# AST1080 register map
File version: 1.0
CPU: CM4 r0p1, little endian, MPU, FPU, 4 interrupt priority bits, 256 interrupts
Registers are 32-bit, read-write, reset 0x0 unless marked. A register's access mark holds for its fields unless they carry their own. Offsets are from the block's base; [hi:lo] are bit positions; {n}, {i} and the like mark numbered series; 'fields as' and 'values as' point back to an identical list.

## spipf
Base 0x74C15000
Same registers: spipf1 0x74C16000, spipf2 0x74C17000
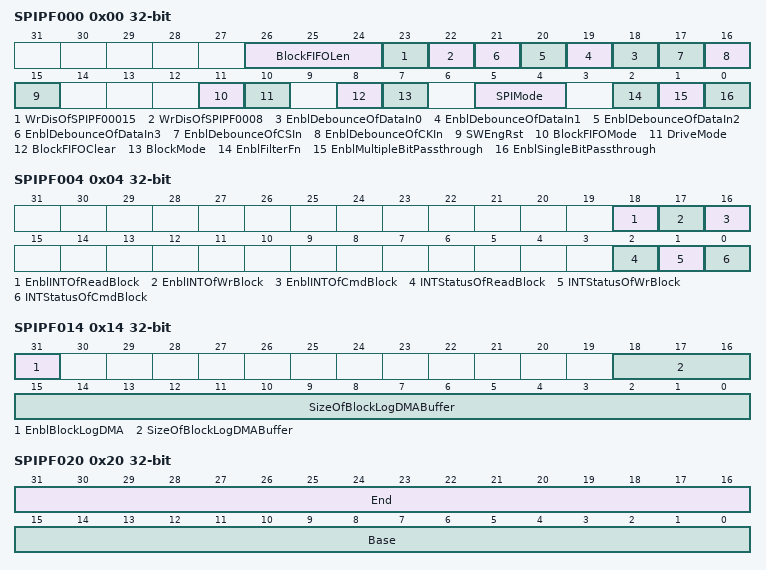
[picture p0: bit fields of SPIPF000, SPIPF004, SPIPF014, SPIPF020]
0x00 SPIPF000 — Engine Control Register
  [26:24] BlockFIFOLen ro — Block FIFO length
  [23] WrDisOfSPIPF00015 — Write Disable of SPIPF000[15]
  [22] WrDisOfSPIPF0008 — Write Disable of SPIPF000[8]
  [n+18] EnblDebounceOfDataIn{n} (n=0..3) — Enable Debounce of DataIn[{n}]
  [17] EnblDebounceOfCSIn — Enable Debounce of CSIn
  [16] EnblDebounceOfCKIn — Enable Debounce of CKIn
  [15] SWEngRst — SW Engine Reset
    1=Reset; 0=NOP
  [11] BlockFIFOMode
    1=Store_The_Latest_The_Lastest_Orverrides; 0=Store_The_Oldest_Stops_When_FIFO_Full
  [10] DriveMode
    1=Drive_DataOut_After_CS_Is_Low; 0=Drive_DataOut0_SPI_Or_DataOut30_QPI_Before_CS_Is_Low
  [8] BlockFIFOClear
    1=Clear_Block_FIFO
  [7] BlockMode
    1=Block_A_Command_By_One_Extra_CLK; 0=Block_A_Command_By_Deasserting_CS_Early
  [5:4] SPIMode
  [2] EnblFilterFn — Enable Filter function
  [1] EnblMultipleBitPassthrough — Enable Multiple Bit Passthrough
  [0] EnblSingleBitPassthrough — Enable Single Bit Passthrough
0x04 SPIPF004 — Interrupt Enable and Status Register
  [18] EnblINTOfReadBlock — Enable Interrupt of Read Block
  [17] EnblINTOfWrBlock — Enable Interrupt of Write Block
  [16] EnblINTOfCmdBlock — Enable Interrupt of Command Block
  [2] INTStatusOfReadBlock — Interrupt Status of Read Block
  [1] INTStatusOfWrBlock — Interrupt Status of Write Block
  [0] INTStatusOfCmdBlock — Interrupt Status of Command Block
0x08 SPIPF008 — EAR and Over Speed Register
  [7:0] CurExtendAddrRegRxdFromSPIMaster ro — Current Extend Address Register Received from SPI master
0x0C SPIPF00C — Block FIFO Data Register
  [31:0] ReadDataOfBlockFIFO ro
0x10 SPIPF010 — Block Log DMA Base Address
  [31:2] BlockLogDMABaseAddr
0x14 SPIPF014 — Block Log DMA Size
  [31] EnblBlockLogDMA — Enable Block Log DMA
  [18:0] SizeOfBlockLogDMABuffer
0x18 SPIPF018 — Block Log DMA Write Pointer
  [17:0] BlockLogDMAWrPointer ro
0x20 SPIPF020 — CS0 range
  [31:16] End, [15:0] Base
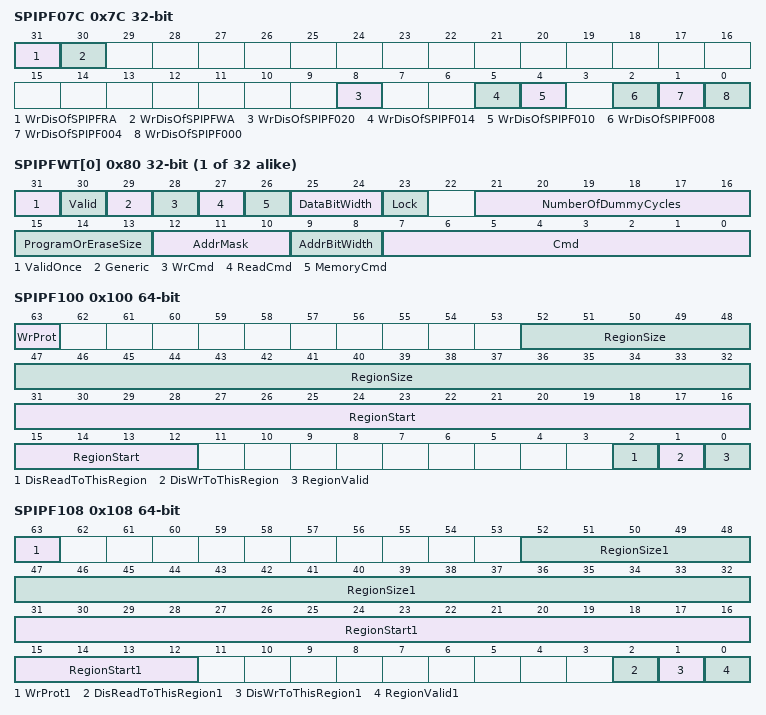
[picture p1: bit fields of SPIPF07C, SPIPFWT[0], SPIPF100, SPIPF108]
0x7C SPIPF07C — Write Disable Register
  [31] WrDisOfSPIPFRA — Write Disable of SPIPFRA
  [30] WrDisOfSPIPFWA — Write Disable of SPIPFWA
  [8] WrDisOfSPIPF020 — Write Disable of SPIPF020
  [5] WrDisOfSPIPF014 — Write Disable of SPIPF014
  [4] WrDisOfSPIPF010 — Write Disable of SPIPF010
  [2] WrDisOfSPIPF008 — Write Disable of SPIPF008
  [1] WrDisOfSPIPF004 — Write Disable of SPIPF004
  [0] WrDisOfSPIPF000 — Write Disable of SPIPF000
{0x80+4i} SPIPFWT[{i}] (i=0..31) — Allow Command Table \#1 $\sim$ \#32
  [31] ValidOnce
    0=0_Comes
  [30] Valid
  [29] Generic
  [28] WrCmd — Write Command
  [27] ReadCmd — Read Command
  [26] MemoryCmd — Memory Command
  [25:24] DataBitWidth
  [23] Lock
  [21:16] NumberOfDummyCycles
  [15:13] ProgramOrEraseSize
  [12:10] AddrMask — Address Mask
  [9:8] AddrBitWidth — Address Bit width
  [7:0] Cmd — Command
0x100 SPIPF100 64-bit — Region 00 setting
  [63] WrProt — Write Protection
  [52:32] RegionSize
  [31:12] RegionStart
  [2] DisReadToThisRegion — Disable Read to this region
  [1] DisWrToThisRegion — Disable Write to this region
  [0] RegionValid
0x108 SPIPF108 64-bit — Region 01 setting
  [63] WrProt1 — Write Protection
  [52:32] RegionSize1 — Region Size
  [31:12] RegionStart1 — Region Start
  [2] DisReadToThisRegion1 — Disable Read to this region
  [1] DisWrToThisRegion1 — Disable Write to this region
  [0] RegionValid1 — Region Valid
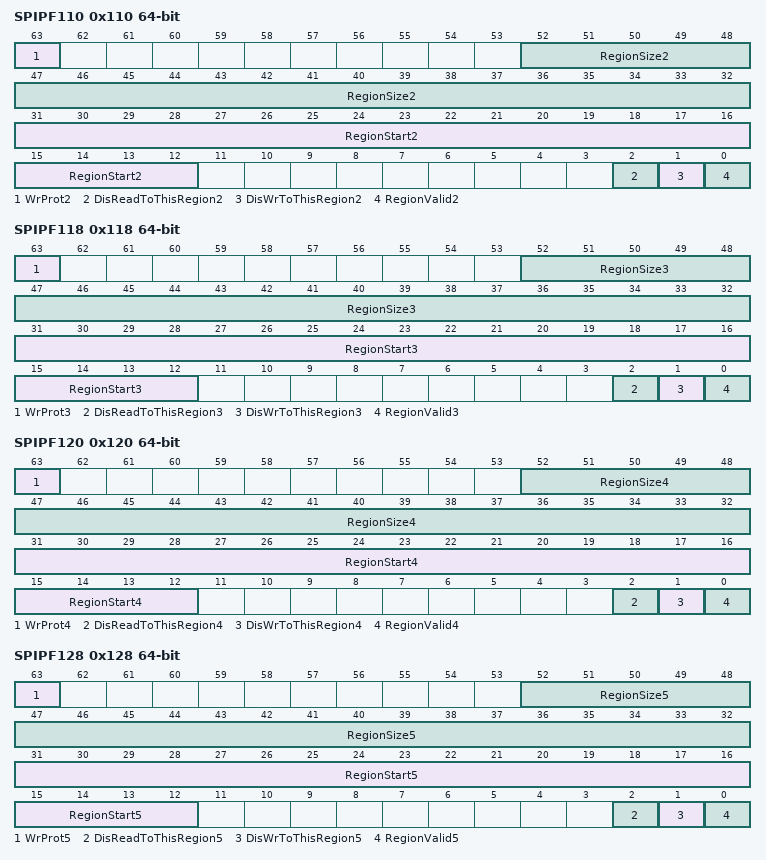
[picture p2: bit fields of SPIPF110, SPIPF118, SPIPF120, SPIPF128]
0x110 SPIPF110 64-bit — Region 02 setting
  [63] WrProt2 — Write Protection
  [52:32] RegionSize2 — Region Size
  [31:12] RegionStart2 — Region Start
  [2] DisReadToThisRegion2 — Disable Read to this region
  [1] DisWrToThisRegion2 — Disable Write to this region
  [0] RegionValid2 — Region Valid
0x118 SPIPF118 64-bit — Region 03 setting
  [63] WrProt3 — Write Protection
  [52:32] RegionSize3 — Region Size
  [31:12] RegionStart3 — Region Start
  [2] DisReadToThisRegion3 — Disable Read to this region
  [1] DisWrToThisRegion3 — Disable Write to this region
  [0] RegionValid3 — Region Valid
0x120 SPIPF120 64-bit — Region 04 setting
  [63] WrProt4 — Write Protection
  [52:32] RegionSize4 — Region Size
  [31:12] RegionStart4 — Region Start
  [2] DisReadToThisRegion4 — Disable Read to this region
  [1] DisWrToThisRegion4 — Disable Write to this region
  [0] RegionValid4 — Region Valid
0x128 SPIPF128 64-bit — Region 05 setting
  [63] WrProt5 — Write Protection
  [52:32] RegionSize5 — Region Size
  [31:12] RegionStart5 — Region Start
  [2] DisReadToThisRegion5 — Disable Read to this region
  [1] DisWrToThisRegion5 — Disable Write to this region
  [0] RegionValid5 — Region Valid
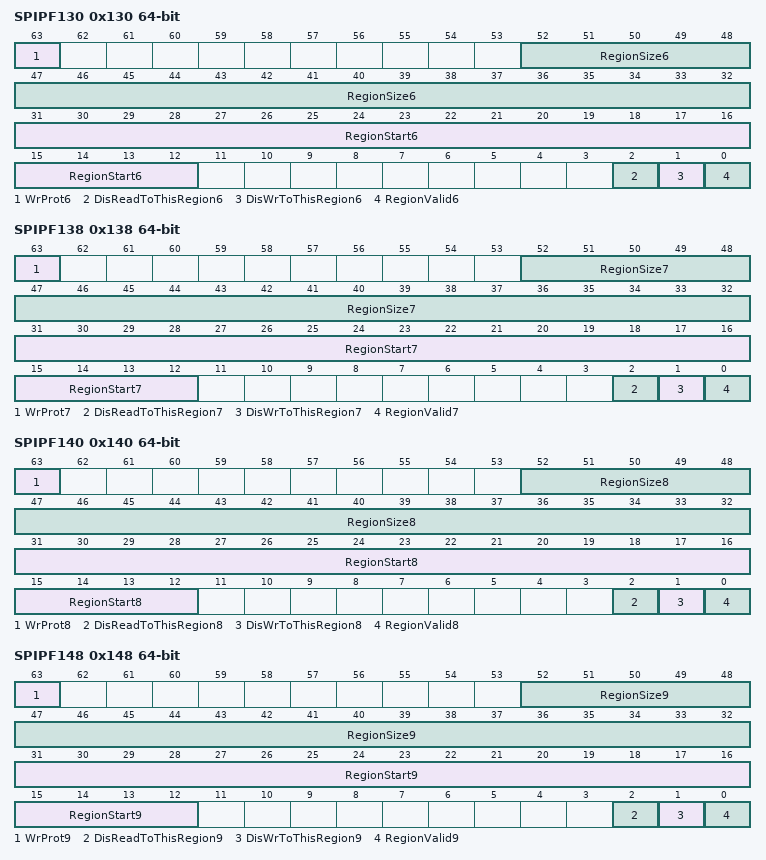
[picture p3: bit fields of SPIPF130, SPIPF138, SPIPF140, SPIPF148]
0x130 SPIPF130 64-bit — Region 06 setting
  [63] WrProt6 — Write Protection
  [52:32] RegionSize6 — Region Size
  [31:12] RegionStart6 — Region Start
  [2] DisReadToThisRegion6 — Disable Read to this region
  [1] DisWrToThisRegion6 — Disable Write to this region
  [0] RegionValid6 — Region Valid
0x138 SPIPF138 64-bit — Region 07 setting
  [63] WrProt7 — Write Protection
  [52:32] RegionSize7 — Region Size
  [31:12] RegionStart7 — Region Start
  [2] DisReadToThisRegion7 — Disable Read to this region
  [1] DisWrToThisRegion7 — Disable Write to this region
  [0] RegionValid7 — Region Valid
0x140 SPIPF140 64-bit — Region 08 setting
  [63] WrProt8 — Write Protection
  [52:32] RegionSize8 — Region Size
  [31:12] RegionStart8 — Region Start
  [2] DisReadToThisRegion8 — Disable Read to this region
  [1] DisWrToThisRegion8 — Disable Write to this region
  [0] RegionValid8 — Region Valid
0x148 SPIPF148 64-bit — Region 09 setting
  [63] WrProt9 — Write Protection
  [52:32] RegionSize9 — Region Size
  [31:12] RegionStart9 — Region Start
  [2] DisReadToThisRegion9 — Disable Read to this region
  [1] DisWrToThisRegion9 — Disable Write to this region
  [0] RegionValid9 — Region Valid
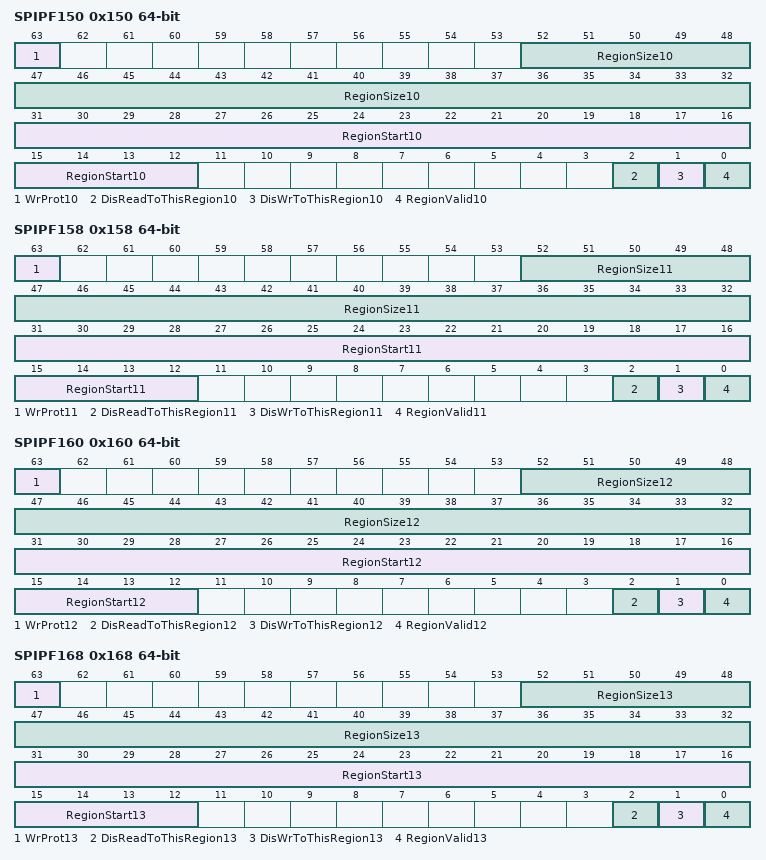
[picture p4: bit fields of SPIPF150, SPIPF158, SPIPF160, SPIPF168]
0x150 SPIPF150 64-bit — Region 10 setting
  [63] WrProt10 — Write Protection
  [52:32] RegionSize10 — Region Size
  [31:12] RegionStart10 — Region Start
  [2] DisReadToThisRegion10 — Disable Read to this region
  [1] DisWrToThisRegion10 — Disable Write to this region
  [0] RegionValid10 — Region Valid
0x158 SPIPF158 64-bit — Region 11 setting
  [63] WrProt11 — Write Protection
  [52:32] RegionSize11 — Region Size
  [31:12] RegionStart11 — Region Start
  [2] DisReadToThisRegion11 — Disable Read to this region
  [1] DisWrToThisRegion11 — Disable Write to this region
  [0] RegionValid11 — Region Valid
0x160 SPIPF160 64-bit — Region 12 setting
  [63] WrProt12 — Write Protection
  [52:32] RegionSize12 — Region Size
  [31:12] RegionStart12 — Region Start
  [2] DisReadToThisRegion12 — Disable Read to this region
  [1] DisWrToThisRegion12 — Disable Write to this region
  [0] RegionValid12 — Region Valid
0x168 SPIPF168 64-bit — Region 13 setting
  [63] WrProt13 — Write Protection
  [52:32] RegionSize13 — Region Size
  [31:12] RegionStart13 — Region Start
  [2] DisReadToThisRegion13 — Disable Read to this region
  [1] DisWrToThisRegion13 — Disable Write to this region
  [0] RegionValid13 — Region Valid
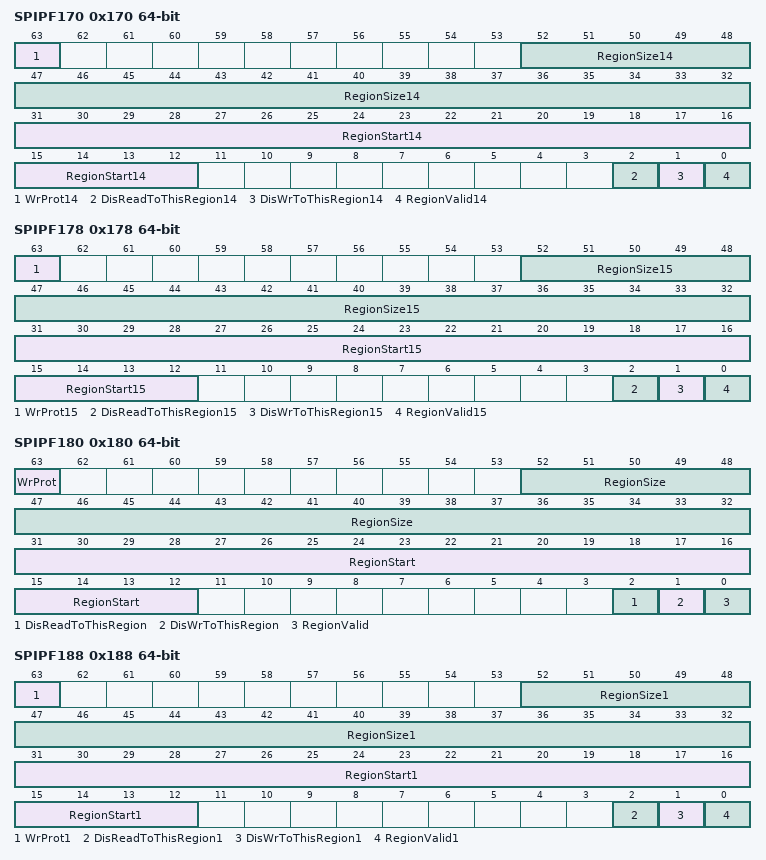
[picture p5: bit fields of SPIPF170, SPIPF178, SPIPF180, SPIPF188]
0x170 SPIPF170 64-bit — Region 14 setting
  [63] WrProt14 — Write Protection
  [52:32] RegionSize14 — Region Size
  [31:12] RegionStart14 — Region Start
  [2] DisReadToThisRegion14 — Disable Read to this region
  [1] DisWrToThisRegion14 — Disable Write to this region
  [0] RegionValid14 — Region Valid
0x178 SPIPF178 64-bit — Region 15 setting
  [63] WrProt15 — Write Protection
  [52:32] RegionSize15 — Region Size
  [31:12] RegionStart15 — Region Start
  [2] DisReadToThisRegion15 — Disable Read to this region
  [1] DisWrToThisRegion15 — Disable Write to this region
  [0] RegionValid15 — Region Valid
0x180 SPIPF180 64-bit — Region 16 setting
  fields as SPIPF100
0x188 SPIPF188 64-bit — Region 17 setting
  fields as SPIPF108
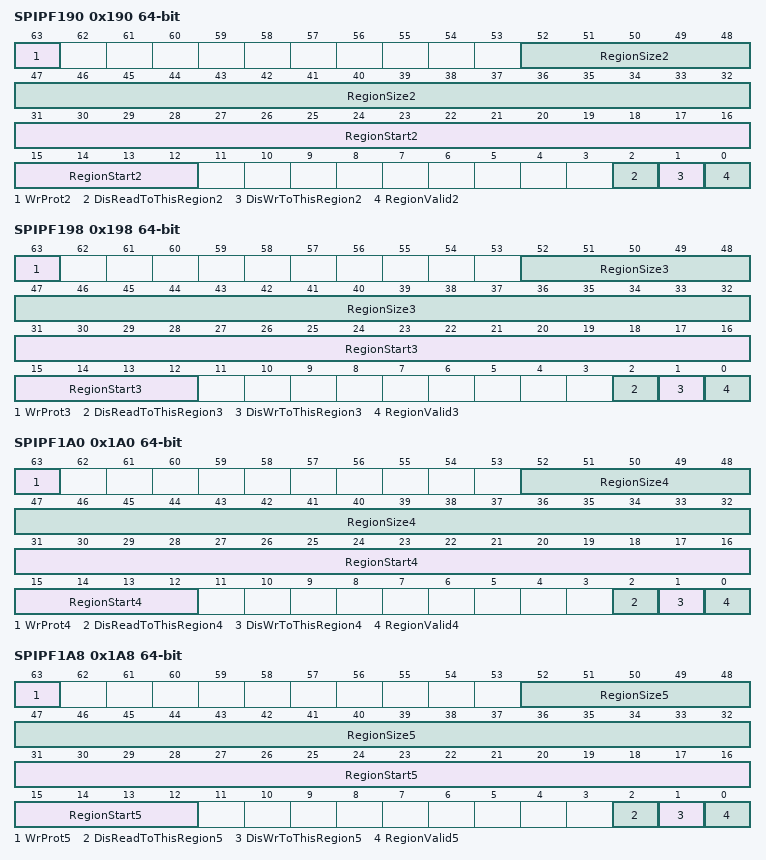
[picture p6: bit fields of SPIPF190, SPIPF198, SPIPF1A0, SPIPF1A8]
0x190 SPIPF190 64-bit — Region 18 setting
  fields as SPIPF110
0x198 SPIPF198 64-bit — Region 19 setting
  fields as SPIPF118
0x1A0 SPIPF1A0 64-bit — Region 20 setting
  fields as SPIPF120
0x1A8 SPIPF1A8 64-bit — Region 21 setting
  fields as SPIPF128
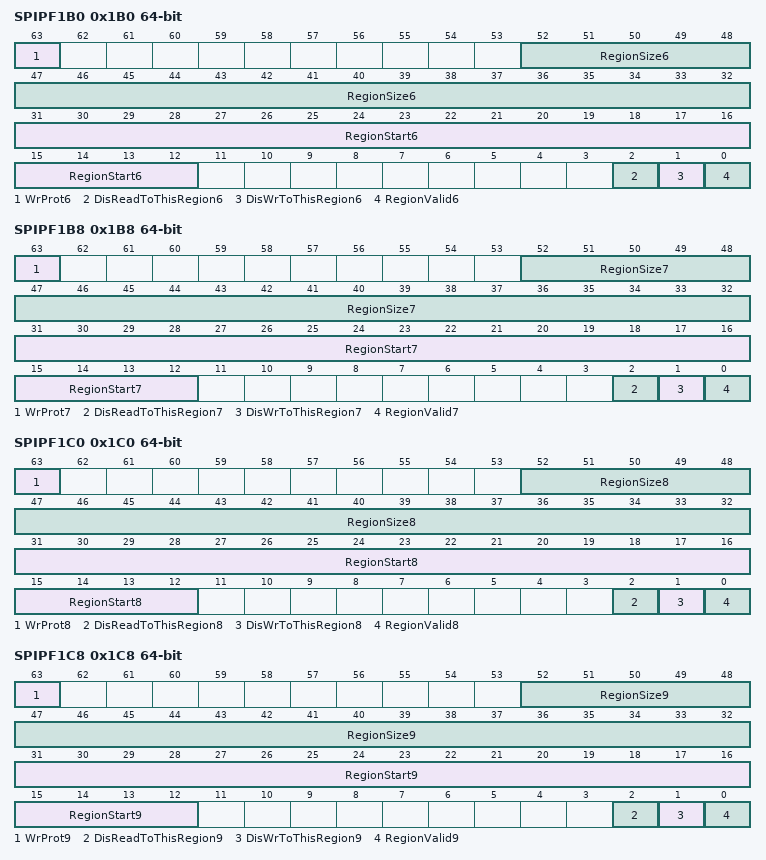
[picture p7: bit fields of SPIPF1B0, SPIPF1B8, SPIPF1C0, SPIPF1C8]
0x1B0 SPIPF1B0 64-bit — Region 22 setting
  fields as SPIPF130
0x1B8 SPIPF1B8 64-bit — Region 23 setting
  fields as SPIPF138
0x1C0 SPIPF1C0 64-bit — Region 24 setting
  fields as SPIPF140
0x1C8 SPIPF1C8 64-bit — Region 25 setting
  fields as SPIPF148
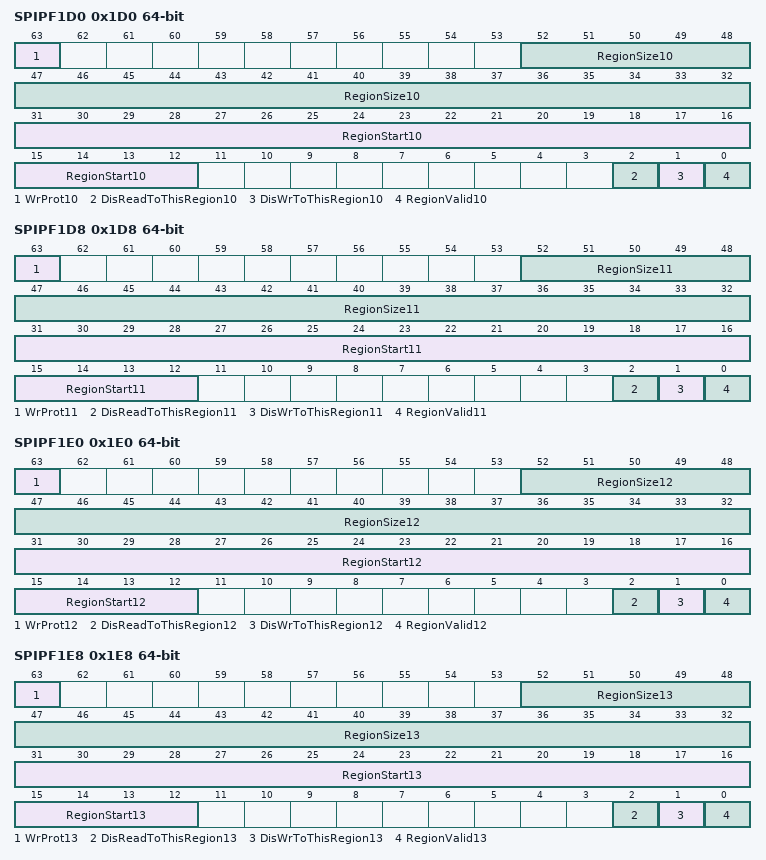
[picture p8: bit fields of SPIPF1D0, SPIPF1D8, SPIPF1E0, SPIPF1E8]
0x1D0 SPIPF1D0 64-bit — Region 26 setting
  fields as SPIPF150
0x1D8 SPIPF1D8 64-bit — Region 27 setting
  fields as SPIPF158
0x1E0 SPIPF1E0 64-bit — Region 28 setting
  fields as SPIPF160
0x1E8 SPIPF1E8 64-bit — Region 29 setting
  fields as SPIPF168
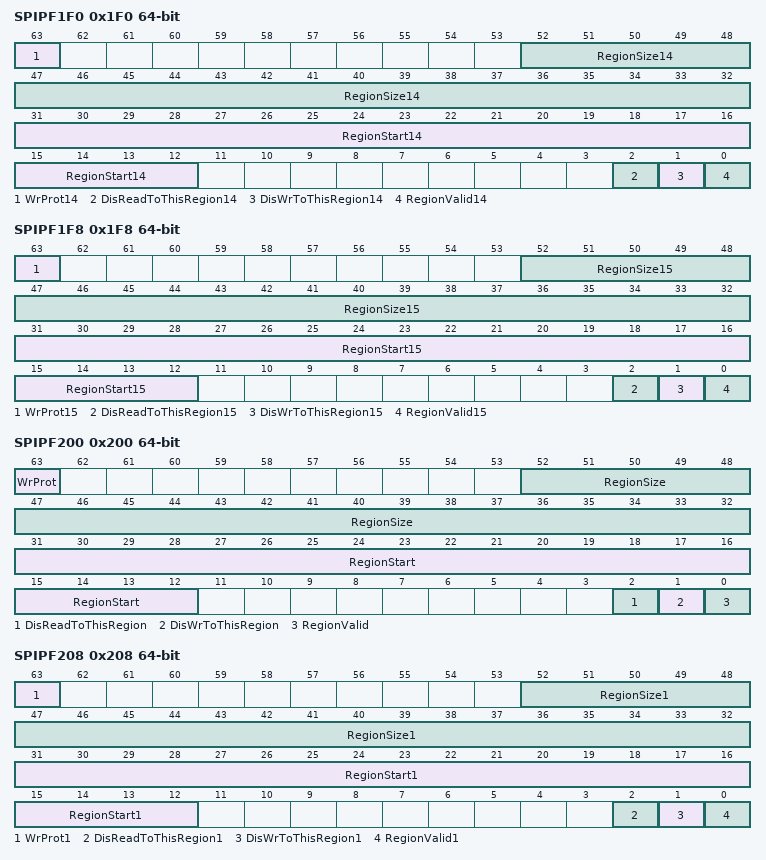
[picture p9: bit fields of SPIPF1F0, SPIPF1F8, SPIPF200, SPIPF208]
0x1F0 SPIPF1F0 64-bit — Region 30 setting
  fields as SPIPF170
0x1F8 SPIPF1F8 64-bit — Region 31 setting
  fields as SPIPF178
0x200 SPIPF200 64-bit — Region 32 setting
  fields as SPIPF100
0x208 SPIPF208 64-bit — Region 33 setting
  fields as SPIPF108
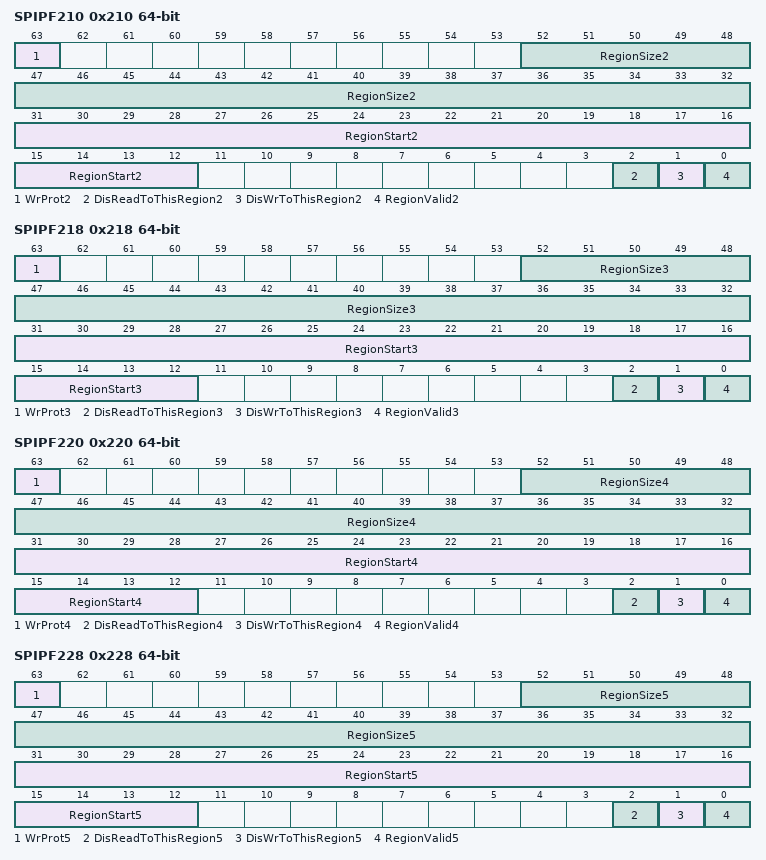
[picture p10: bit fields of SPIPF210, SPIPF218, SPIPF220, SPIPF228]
0x210 SPIPF210 64-bit — Region 34 setting
  fields as SPIPF110
0x218 SPIPF218 64-bit — Region 35 setting
  fields as SPIPF118
0x220 SPIPF220 64-bit — Region 36 setting
  fields as SPIPF120
0x228 SPIPF228 64-bit — Region 37 setting
  fields as SPIPF128
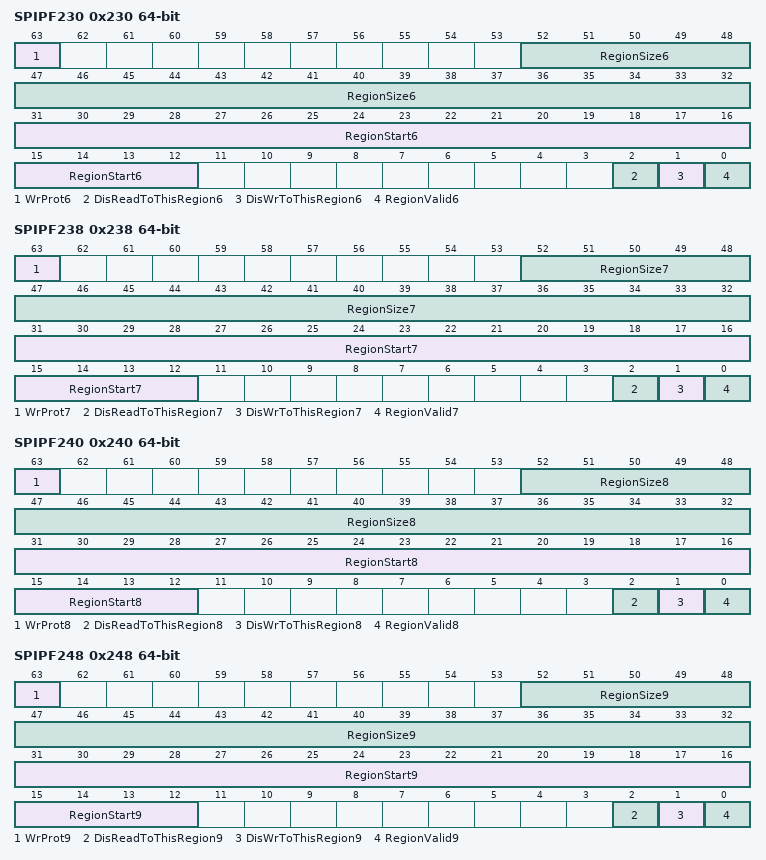
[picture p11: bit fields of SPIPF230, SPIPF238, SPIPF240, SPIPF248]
0x230 SPIPF230 64-bit — Region 38 setting
  fields as SPIPF130
0x238 SPIPF238 64-bit — Region 39 setting
  fields as SPIPF138
0x240 SPIPF240 64-bit — Region 40 setting
  fields as SPIPF140
0x248 SPIPF248 64-bit — Region 41 setting
  fields as SPIPF148
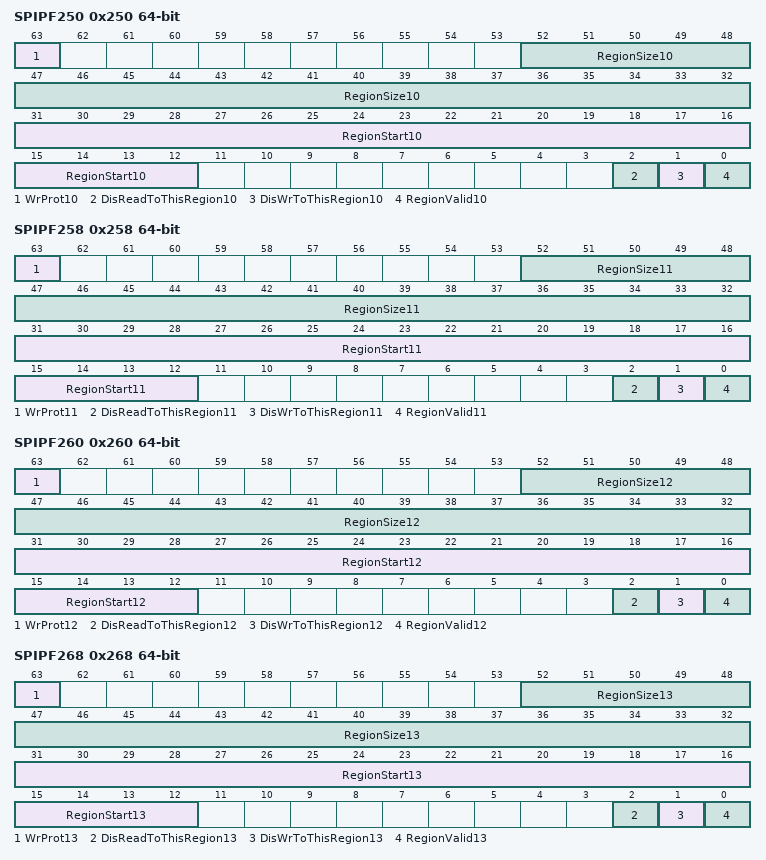
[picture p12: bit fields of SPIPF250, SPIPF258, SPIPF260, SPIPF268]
0x250 SPIPF250 64-bit — Region 42 setting
  fields as SPIPF150
0x258 SPIPF258 64-bit — Region 43 setting
  fields as SPIPF158
0x260 SPIPF260 64-bit — Region 44 setting
  fields as SPIPF160
0x268 SPIPF268 64-bit — Region 45 setting
  fields as SPIPF168
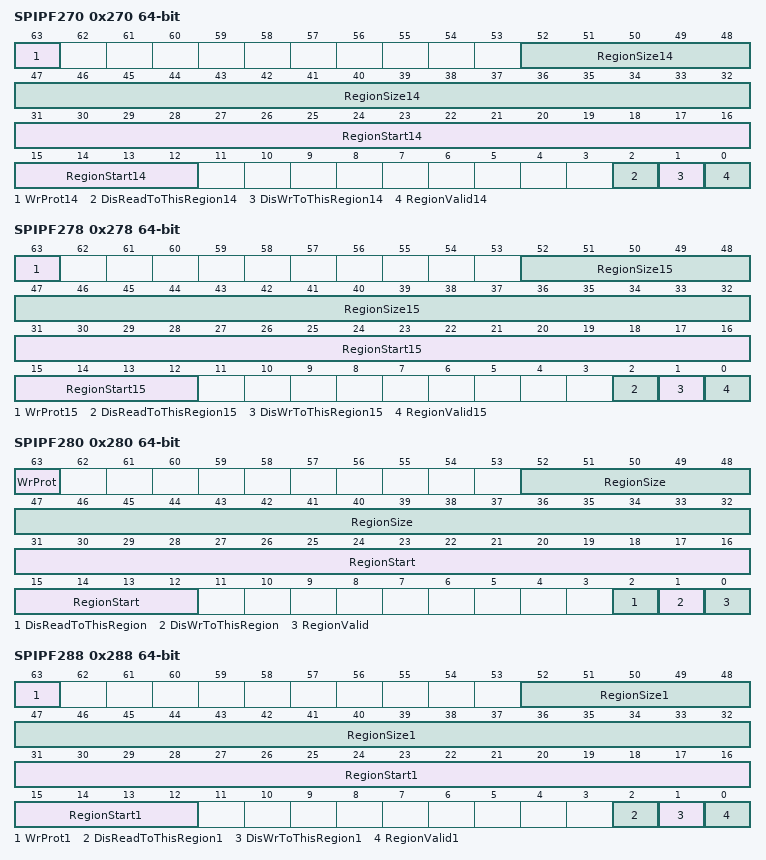
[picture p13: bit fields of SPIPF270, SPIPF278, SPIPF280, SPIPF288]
0x270 SPIPF270 64-bit — Region 46 setting
  fields as SPIPF170
0x278 SPIPF278 64-bit — Region 47 setting
  fields as SPIPF178
0x280 SPIPF280 64-bit — Region 48 setting
  fields as SPIPF100
0x288 SPIPF288 64-bit — Region 49 setting
  fields as SPIPF108
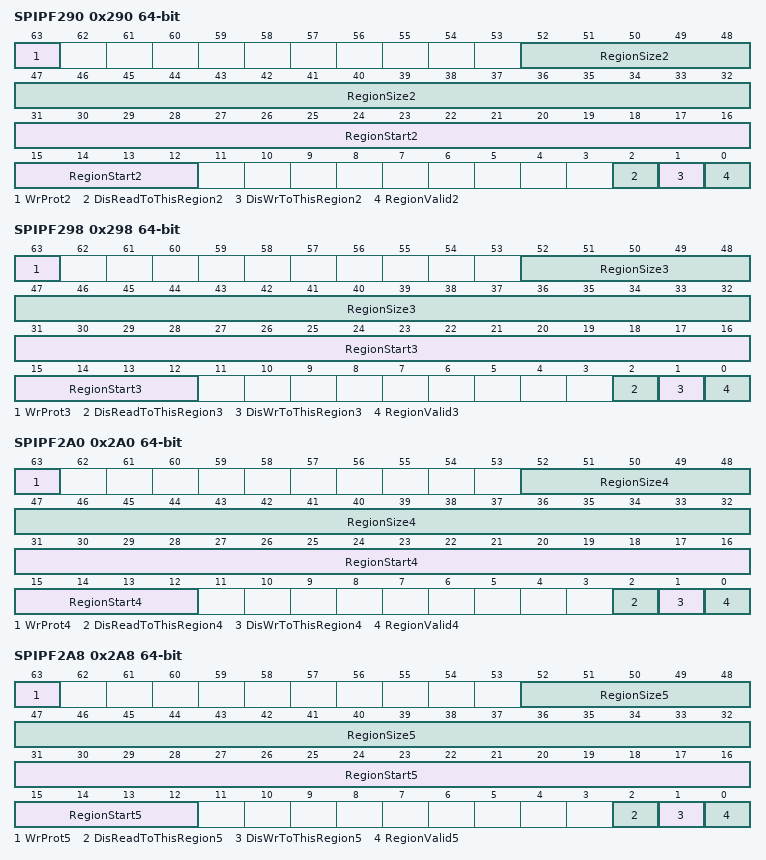
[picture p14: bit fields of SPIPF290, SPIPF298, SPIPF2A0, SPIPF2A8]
0x290 SPIPF290 64-bit — Region 50 setting
  fields as SPIPF110
0x298 SPIPF298 64-bit — Region 51 setting
  fields as SPIPF118
0x2A0 SPIPF2A0 64-bit — Region 52 setting
  fields as SPIPF120
0x2A8 SPIPF2A8 64-bit — Region 53 setting
  fields as SPIPF128
0x2B0 SPIPF2B0 64-bit — Region 54 setting
  fields as SPIPF130
0x2B8 SPIPF2B8 64-bit — Region 55 setting
  fields as SPIPF138
0x2C0 SPIPF2C0 64-bit — Region 56 setting
  fields as SPIPF140
0x2C8 SPIPF2C8 64-bit — Region 57 setting
  fields as SPIPF148
0x2D0 SPIPF2D0 64-bit — Region 58 setting
  fields as SPIPF150
0x2D8 SPIPF2D8 64-bit — Region 59 setting
  fields as SPIPF158
0x2E0 SPIPF2E0 64-bit — Region 60 setting
  fields as SPIPF160
0x2E8 SPIPF2E8 64-bit — Region 61 setting
  fields as SPIPF168
0x2F0 SPIPF2F0 64-bit — Region 62 setting
  fields as SPIPF170
0x2F8 SPIPF2F8 64-bit — Region 63 setting
  fields as SPIPF178
